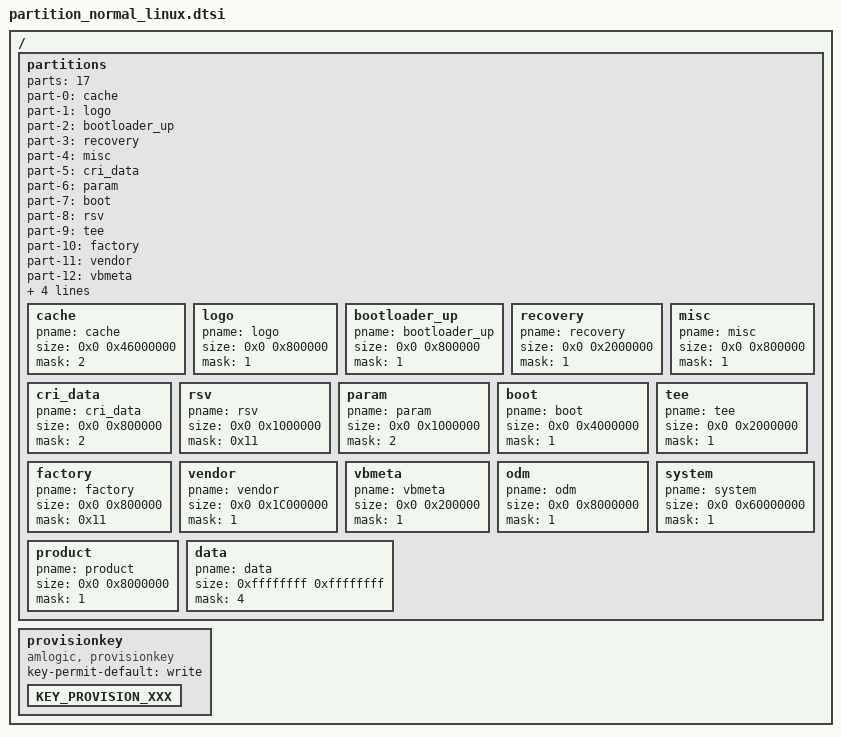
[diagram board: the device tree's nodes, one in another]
// SPDX-License-Identifier: (GPL-2.0+ OR MIT)
/*
 * Amlogic partition set for normal
 *
 * Copyright (c) 2017-2017 Amlogic Ltd
 *
 * This file is licensed under a dual GPLv2 or BSD license.
 *
 */

/ {
    partitions: partitions{
		parts = <17>;
		part-0 = <&cache>;
		part-1 = <&logo>;
		part-2 = <&bootloader_up>;
		part-3 = <&recovery>;
		part-4 = <&misc>;
		part-5 = <&cri_data>;
		part-6 = <&param>;
		part-7 = <&boot>;
		part-8 = <&rsv>;
		part-9 = <&tee>;
		part-10 = <&factory>;
		part-11 = <&vendor>;
		part-12 = <&vbmeta>;
		part-13 = <&odm>;
		part-14 = <&system>;
		part-15 = <&product>;
		part-16 = <&data>;

		cache:cache
		{
			pname = "cache";
			size = <0x0 0x46000000>;
			mask = <2>;
		};
		logo:logo{
			pname = "logo";
			size = <0x0 0x800000>;
			mask = <1>;
		};
		bootloader_up:bootloader_up{
			pname = "bootloader_up";
			size = <0x0 0x800000>;
			mask = <1>;
		};
		recovery:recovery{
			pname = "recovery";
			size = <0x0 0x2000000>;
			mask = <1>;
		};
		misc:misc{
			pname = "misc";
			size = <0x0 0x800000>;
			mask = <1>;
		};
		cri_data:cri_data
		{
			pname = "cri_data";
			size = <0x0 0x800000>;
			mask = <2>;
		};
		rsv:rsv{
			pname = "rsv";
			size = <0x0 0x1000000>;
			mask = <0x11>;
		};
		param:param{
			pname = "param";
			size = <0x0 0x1000000>;
			mask = <2>;
		};
		boot:boot
		{
			pname = "boot";
			size = <0x0 0x4000000>;
			mask = <1>;
		};
		tee:tee{
			pname = "tee";
			size = <0x0 0x2000000>;
			mask = <1>;
		};
		factory:factory{
			pname = "factory";
			size = <0x0 0x800000>;
			mask = <0x11>;
		};
		vendor:vendor
		{
			pname = "vendor";
			size = <0x0 0x1C000000>;
			mask = <1>;
		};
		vbmeta:vbmeta
		{
			pname = "vbmeta";
			size = <0x0 0x200000>;
			mask = <1>;
		};
		odm:odm
		{
			pname = "odm";
			size = <0x0 0x8000000>;
			mask = <1>;
		};
		system:system
		{
			pname = "system";
			size = <0x0 0x60000000>;
			mask = <1>;
		};
		product:product{
			pname = "product";
			size = <0x0 0x8000000>;
			mask = <1>;
		};
		data:data
		{
			pname = "data";
			size = <0xffffffff 0xffffffff>;
			mask = <4>;
		};
	};

	provisionkey {
		compatible = "amlogic, provisionkey";
		status = "okay";
		key-permit-default = "write";
		//new key not need add dts if started with KEY_PROVISION_
		KEY_PROVISION_XXX { };
		//test_my_added_keyname { };
	};//End provisionkey

};/* end of / */
